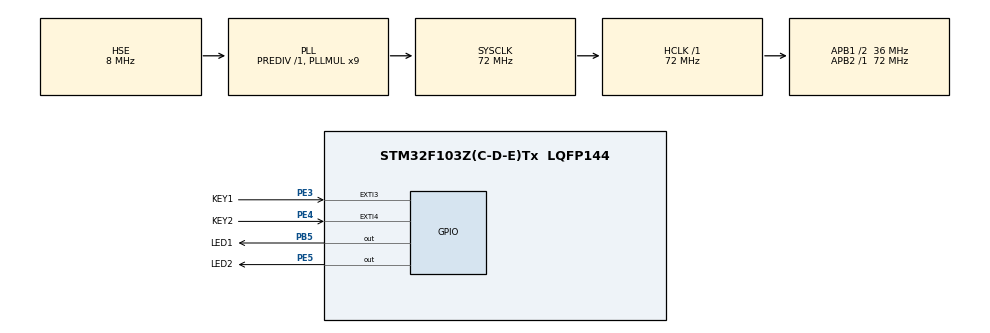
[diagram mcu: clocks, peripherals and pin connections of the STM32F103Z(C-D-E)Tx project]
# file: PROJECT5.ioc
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Mcu.Family=STM32F1
Mcu.Name=STM32F103Z(C-D-E)Tx
Mcu.Package=LQFP144
NVIC.EXTI4_IRQn=true\:15\:0\:true\:false\:true\:true\:true\:true
NVIC.PriorityGroup=NVIC_PRIORITYGROUP_4
OSC_IN.Mode=HSE-External-Oscillator
OSC_IN.Signal=RCC_OSC_IN
OSC_OUT.Mode=HSE-External-Oscillator
OSC_OUT.Signal=RCC_OSC_OUT
PB5.GPIO_Label=LED1
PB5.PinState=GPIO_PIN_SET
PB5.Signal=GPIO_Output
PE3.GPIO_Label=KEY1
PE3.GPIO_ModeDefaultEXTI=GPIO_MODE_IT_FALLING
PE3.Signal=GPXTI3
PE4.GPIO_Label=KEY2
PE4.GPIO_ModeDefaultEXTI=GPIO_MODE_IT_FALLING
PE4.Signal=GPXTI4
PE5.GPIO_Label=LED2
PE5.PinState=GPIO_PIN_SET
PE5.Signal=GPIO_Output
ProjectManager.HeapSize=0x200
ProjectManager.StackSize=0x400
ProjectManager.TargetToolchain=MDK-ARM V5.32
RCC.AHBFreq_Value=72000000
RCC.APB1CLKDivider=RCC_HCLK_DIV2
RCC.APB1Freq_Value=36000000
RCC.APB1TimFreq_Value=72000000
RCC.APB2Freq_Value=72000000
RCC.APB2TimFreq_Value=72000000
RCC.HCLKFreq_Value=72000000
RCC.PLLMUL=RCC_PLL_MUL9
RCC.PLLSourceVirtual=RCC_PLLSOURCE_HSE
RCC.RCC_MCOSource=RCC_MCO1SOURCE_PLLCLK
RCC.SYSCLKFreq_VALUE=72000000
RCC.SYSCLKSource=RCC_SYSCLKSOURCE_PLLCLK
RCC.USBFreq_Value=72000000
VP_SYS_VS_ND.Mode=No_Debug
board=custom

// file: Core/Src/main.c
/* USER CODE BEGIN Header */
/**
  ******************************************************************************
  * @file           : main.c
  * @brief          : Main program body
  ******************************************************************************
  * @attention
  *
  * Copyright (c) 2024 STMicroelectronics.
  * All rights reserved.
  *
  * This software is licensed under terms that can be found in the LICENSE file
  * in the root directory of this software component.
  * If no LICENSE file comes with this software, it is provided AS-IS.
  *
  ******************************************************************************
  */
/* USER CODE END Header */
#include "main.h"

void SystemClock_Config(void);
static void MX_GPIO_Init(void);

/* USER CODE BEGIN 0 */
//uint16_t Num;
/* USER CODE END 0 */

int main(void)
{
  /* USER CODE BEGIN 1 */
	//Num=0;
  /* USER CODE END 1 */

  /* MCU Configuration--------------------------------------------------------*/

  /* Reset of all peripherals, Initializes the Flash interface and the Systick. */
  HAL_Init();

  /* Configure the system clock */
  SystemClock_Config();

  /* Initialize all configured peripherals */
  MX_GPIO_Init();
  /* USER CODE BEGIN 2 */
//HAL_TIM_Base_Start_IT(&htim4);//使能定时器4中断
  /* USER CODE END 2 */

  /* Infinite loop */
  /* USER CODE BEGIN WHILE */
  while (1)
  {if(HAL_GPIO_ReadPin(KEY1_GPIO_Port,KEY1_Pin)==GPIO_PIN_RESET)
		{
		HAL_GPIO_WritePin(LED1_GPIO_Port,LED1_Pin,GPIO_PIN_SET);
		HAL_GPIO_WritePin(LED2_GPIO_Port,LED2_Pin,GPIO_PIN_RESET);
		HAL_Delay(200);
		HAL_GPIO_WritePin(LED1_GPIO_Port,LED1_Pin,GPIO_PIN_RESET);
		HAL_GPIO_WritePin(LED2_GPIO_Port,LED2_Pin,GPIO_PIN_SET);
		HAL_Delay(200);
		}
		else if(HAL_GPIO_ReadPin(KEY2_GPIO_Port,KEY2_Pin)==GPIO_PIN_RESET)
		{
		HAL_GPIO_WritePin(LED1_GPIO_Port,LED1_Pin,GPIO_PIN_SET);
		HAL_GPIO_WritePin(LED2_GPIO_Port,LED2_Pin,GPIO_PIN_RESET);
		HAL_Delay(2000);
		HAL_GPIO_WritePin(LED1_GPIO_Port,LED1_Pin,GPIO_PIN_RESET);
		HAL_GPIO_WritePin(LED2_GPIO_Port,LED2_Pin,GPIO_PIN_SET);
		HAL_Delay(2000);
		}
    /* USER CODE END WHILE */

  }
}

void SystemClock_Config(void)
{
  RCC_OscInitTypeDef RCC_OscInitStruct = {0};
  RCC_ClkInitTypeDef RCC_ClkInitStruct = {0};

  /** Initializes the RCC Oscillators according to the specified parameters
  * in the RCC_OscInitTypeDef structure.
  */
  RCC_OscInitStruct.OscillatorType = RCC_OSCILLATORTYPE_HSE;
  RCC_OscInitStruct.HSEState = RCC_HSE_ON;
  RCC_OscInitStruct.HSEPredivValue = RCC_HSE_PREDIV_DIV1;
  RCC_OscInitStruct.HSIState = RCC_HSI_ON;
  RCC_OscInitStruct.PLL.PLLState = RCC_PLL_ON;
  RCC_OscInitStruct.PLL.PLLSource = RCC_PLLSOURCE_HSE;
  RCC_OscInitStruct.PLL.PLLMUL = RCC_PLL_MUL9;
  if (HAL_RCC_OscConfig(&RCC_OscInitStruct) != HAL_OK)
  {
    Error_Handler();
  }

  /** Initializes the CPU, AHB and APB buses clocks
  */
  RCC_ClkInitStruct.ClockType = RCC_CLOCKTYPE_HCLK|RCC_CLOCKTYPE_SYSCLK
                              |RCC_CLOCKTYPE_PCLK1|RCC_CLOCKTYPE_PCLK2;
  RCC_ClkInitStruct.SYSCLKSource = RCC_SYSCLKSOURCE_PLLCLK;
  RCC_ClkInitStruct.AHBCLKDivider = RCC_SYSCLK_DIV1;
  RCC_ClkInitStruct.APB1CLKDivider = RCC_HCLK_DIV2;
  RCC_ClkInitStruct.APB2CLKDivider = RCC_HCLK_DIV1;

  if (HAL_RCC_ClockConfig(&RCC_ClkInitStruct, FLASH_LATENCY_2) != HAL_OK)
  {
    Error_Handler();
  }
}

static void MX_GPIO_Init(void)
{
  GPIO_InitTypeDef GPIO_InitStruct = {0};

  /* GPIO Ports Clock Enable */
  __HAL_RCC_GPIOE_CLK_ENABLE();
  __HAL_RCC_GPIOB_CLK_ENABLE();

  /*Configure GPIO pin Output Level */
  HAL_GPIO_WritePin(LED2_GPIO_Port, LED2_Pin, GPIO_PIN_SET);

  /*Configure GPIO pin Output Level */
  HAL_GPIO_WritePin(LED1_GPIO_Port, LED1_Pin, GPIO_PIN_SET);

  /*Configure GPIO pins : KEY1_Pin KEY2_Pin */
  GPIO_InitStruct.Pin = KEY1_Pin|KEY2_Pin;
  GPIO_InitStruct.Mode = GPIO_MODE_IT_FALLING;
  GPIO_InitStruct.Pull = GPIO_NOPULL;
  HAL_GPIO_Init(GPIOE, &GPIO_InitStruct);

  /*Configure GPIO pin : LED2_Pin */
  GPIO_InitStruct.Pin = LED2_Pin;
  GPIO_InitStruct.Mode = GPIO_MODE_OUTPUT_PP;
  GPIO_InitStruct.Pull = GPIO_NOPULL;
  GPIO_InitStruct.Speed = GPIO_SPEED_FREQ_LOW;
  HAL_GPIO_Init(LED2_GPIO_Port, &GPIO_InitStruct);

  /*Configure GPIO pin : LED1_Pin */
  GPIO_InitStruct.Pin = LED1_Pin;
  GPIO_InitStruct.Mode = GPIO_MODE_OUTPUT_PP;
  GPIO_InitStruct.Pull = GPIO_NOPULL;
  GPIO_InitStruct.Speed = GPIO_SPEED_FREQ_LOW;
  HAL_GPIO_Init(LED1_GPIO_Port, &GPIO_InitStruct);

  /* EXTI interrupt init*/
  HAL_NVIC_SetPriority(EXTI4_IRQn, 15, 0);
  HAL_NVIC_EnableIRQ(EXTI4_IRQn);

}

void Error_Handler(void)
{
  __disable_irq();
  while (1)
  {
  }
}
